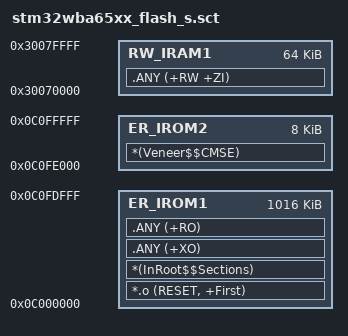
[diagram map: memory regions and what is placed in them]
; *********************************************************************************
; *** Scatter-Loading Description File generated by STM32CubeMX/LinkerGenerator ***
; *********************************************************************************;

LR_IROM1 0x0c000000 0x000fe000  {  ; load_region size_region
  ER_IROM1 0x0c000000 0x000fe000  {  ; load address = excetion address
   *.o (RESET, +First)
   *(InRoot$$Sections)
   .ANY (+XO)
   .ANY (+RO)
  }
  RW_IRAM1 0x30070000 0x00010000  {  ; load address = excetion address
   .ANY (+RW +ZI)
  }
;***region***;
;***endregion***;
}

LR_IROM2 0x0c0fe000 0x00002000  {  ; load_region size_region
  ER_IROM2 0x0c0fe000 0x00002000  {  ; load address = excetion address
   *(Veneer$$CMSE)
  }
}


/*-Start of  regions- Auto-generated By STM32CubeMX-*/
